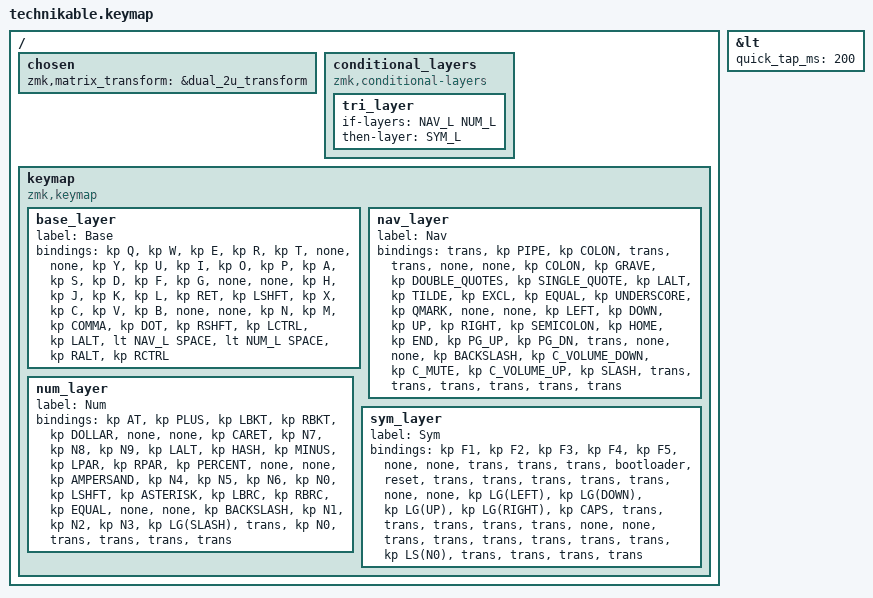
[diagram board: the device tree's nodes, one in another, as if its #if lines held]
/*
 * Copyright (c) 2022 Pete Johanson
 *
 * SPDX-License-Identifier: MIT
 */

#include <behaviors.dtsi>
#include <dt-bindings/zmk/keys.h>
#include <dt-bindings/zmk/bt.h>
#include <dt-bindings/zmk/outputs.h>

#define QWERTY_BASE 1

#define TBLE_ORTHO   true
// #define TBLE_MIT     true
// #define TBLE_DUAL_2U true

#define BAS_L 0
#define NAV_L 1
#define NUM_L 2
#define SYM_L 3

// Using layer taps on thumbs, having quick tap as well helps w/ repeating space/backspace
&lt { quick_tap_ms = <200>; };

#define BT(n) BT_SEL n

/ {
    chosen {
       zmk,matrix_transform =
#ifdef TBLE_DUAL_2U
                       &dual_2u_transform;
#elif defined(TBLE_MIT)
                       &mit_transform;
#else
                       &ortho_transform;
#endif
    };

    conditional_layers {
        compatible = "zmk,conditional-layers";
	tri_layer {
	    if-layers = <NAV_L NUM_L>;
	    then-layer = <SYM_L>;
	};
    };

    keymap {
        compatible = "zmk,keymap";

        base_layer {
            label = "Base";
            bindings = <
#ifdef QWERTY_BASE
 &kp Q    &kp W      &kp E      &kp R       &kp T          &none          &none            &kp Y          &kp U       &kp I      &kp O      &kp P
 &kp A    &kp S      &kp D      &kp F       &kp G          &none          &none            &kp H          &kp J       &kp K      &kp L      &kp RET
 &kp LSHFT  &kp X      &kp C      &kp V       &kp B          &none          &none            &kp N        &kp M       &kp COMMA   &kp DOT       &kp RSHFT
#else
 &kp ESC    &kp Q      &kp W      &kp F       &kp P          &kp B          &kp J            &kp L          &kp U       &kp Y      &kp QUOT     &kp BKSP
 &kp TAB    &kp A      &kp R      &kp S       &kp T          &kp G          &kp M            &kp N          &kp E       &kp I      &kp O        &kp QUOT
 &kp LSHFT  &kp Z      &kp X      &kp C       &kp D          &kp V          &kp K            &kp H          &kp COMMA   &kp DOT    &kp FSLH     &kp RET
#endif
#ifdef TBLE_DUAL_2U
                       &kp LCTRL  &kp LALT      &lt NAV_L SPACE                &lt NUM_L SPACE              &kp RALT    &kp RCTRL
#elif defined(TBLE_MIT)
                       &kp LCTRL  &kp LALT    &mo NAV_L          &kp SPACE                   &mo NUM_L      &kp RALT    &kp RCTRL
#else
                       &mt LGUI ESC  &mo NAV_L    &kp SPACE      &none      &none        &kp BKSP         &mo NUM_L     &mt LCTRL Z   
#endif
            >;
        };

        nav_layer {
            label = "Nav";
            bindings = <
	    
&trans     &kp PIPE     &kp COLON     &trans      &trans          &none       &none     &kp COLON        &kp GRAVE      &kp DOUBLE_QUOTES     &kp SINGLE_QUOTE     &kp LALT
&kp TILDE     &kp EXCL     &kp EQUAL     &kp UNDERSCORE      &kp QMARK          &none       &none     &kp LEFT       &kp DOWN    &kp UP   &kp RIGHT   &kp SEMICOLON
&kp HOME     &kp END  &kp PG_UP  &kp PG_DN   &trans       &none    &none     &kp BACKSLASH       &kp C_VOLUME_DOWN   &kp C_MUTE  &kp C_VOLUME_UP    &kp SLASH
#ifdef TBLE_DUAL_2U
                      &trans     &trans              &trans                    &trans       &trans         &trans
#elif defined(TBLE_MIT)
                      &trans     &trans      &trans                &trans             &trans      &trans   &trans
#else
                      &trans     &trans      &trans         &none       &none        &kp LA(BKSP)     &trans         &trans
#endif
            >;
        };

        num_layer {
            label = "Num";
            bindings = <
&kp AT     &kp PLUS   &kp LBKT     &kp RBKT      &kp DOLLAR    &none    &none    &kp CARET         &kp N7       &kp N8       &kp N9     &kp LALT
&kp HASH     &kp MINUS  &kp LPAR     &kp RPAR      &kp PERCENT    &none   &none    &kp AMPERSAND         &kp N4       &kp N5       &kp N6     &kp N0
&kp LSHFT     &kp ASTERISK  &kp LBRC     &kp RBRC      &kp EQUAL    &none    &none        &kp BACKSLASH         &kp N1       &kp N2       &kp N3     &kp LG(SLASH)
#ifdef TBLE_DUAL_2U
                     &trans     &kp N0              &trans                 &trans            &trans         &trans
#elif defined(TBLE_MIT)
                     &trans     &kp N0      &trans           &none            &kp ESC        &kp DEL      &trans
#else
                     &trans     &trans      &kp TAB    &none         &none     &trans        &trans      &kp LC(G)
#endif
            >;
        };

        sym_layer {
            label = "Sym";
            bindings = <
&kp F1     &kp F2      &kp F3     &kp F4      &kp F5   &none     &none     &trans    &trans       &trans       &bootloader     &reset
&trans     &trans     &trans     &trans  &trans   &none     &none     &kp LG(LEFT)    &kp LG(DOWN)       &kp LG(UP)       &kp LG(RIGHT)     &kp CAPS
&trans     &trans     &trans     &trans  &trans   &none     &none     &trans    &trans       &trans       &trans     &trans
#ifdef TBLE_DUAL_2U
                      &trans     &kp LS(N0)              &trans                    &trans       &trans         &trans
#elif defined(TBLE_MIT)
                      &trans     &kp LS(N0)      &trans                &trans             &trans      &trans   &trans
#else
                      &trans     &trans      &trans          &trans       &trans    &trans        &trans         &trans
#endif
            >;
        };

    };
};

